# ESP32S31_RADIO register map
Vendor: Espressif; Series: ESP32-S31; File version: 3.52
Registers are 32-bit, read-write, no defined reset value unless marked. A register's access mark holds for its fields unless they carry their own. Offsets are from the block's base; [hi:lo] are bit positions.

## WIFI_MAC_POWER_INTERRUPT — WDEVPWR interrupt bank named by complete print_isr_regs. Complete hal_pwr_interrupt_get_event and hal_pwr_interrupt_clr_event independently prove the masked STATUS read and full-width CLEAR acknowledgement transaction. Complete TSF timer enable/disable leaves update the timer interrupt masks in ENABLE and clear stale events through CLEAR.
Base 0x2010D8B4
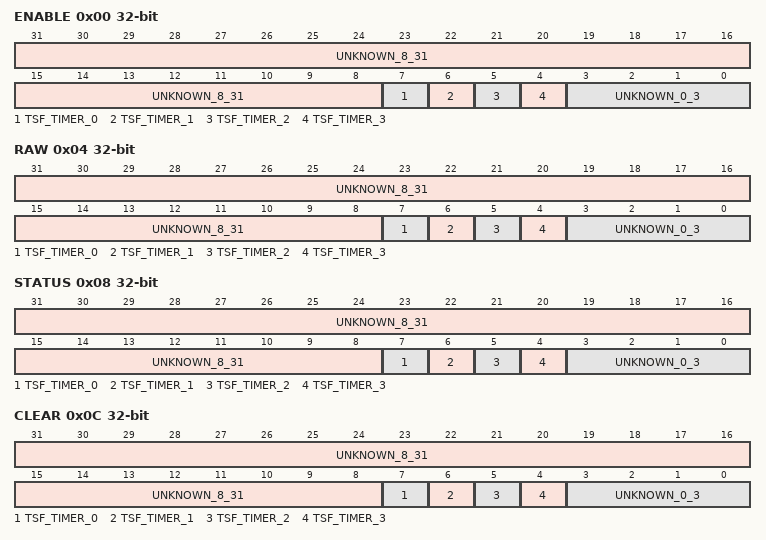
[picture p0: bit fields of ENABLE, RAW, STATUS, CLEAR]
0x00 ENABLE — WDEVPWR_ENABLE diagnostic snapshot and writable event mask. Complete guarded TSF-timer leaves independently identify bits 7 through 4.
  [31:8] UNKNOWN_8_31 — Enable bits whose event identities remain unknown.
  [7] TSF_TIMER_0 — Enable the guarded TSF timer-zero event.
  [6] TSF_TIMER_1 — Enable the guarded TSF timer-one event.
  [5] TSF_TIMER_2 — Enable the guarded TSF timer-two event.
  [4] TSF_TIMER_3 — Enable the guarded TSF timer-three event.
  [3:0] UNKNOWN_0_3 — Enable bits whose event identities remain unknown.
0x04 RAW ro — WDEVPWR_RAW diagnostic snapshot with the same event geometry as ENABLE, STATUS and CLEAR.
  [31:8] UNKNOWN_8_31 — Raw event bits whose identities remain unknown.
  [7] TSF_TIMER_0 — Raw guarded TSF timer-zero event.
  [6] TSF_TIMER_1 — Raw guarded TSF timer-one event.
  [5] TSF_TIMER_2 — Raw guarded TSF timer-two event.
  [4] TSF_TIMER_3 — Raw guarded TSF timer-three event.
  [3:0] UNKNOWN_0_3 — Raw event bits whose identities remain unknown.
0x08 STATUS ro — Masked WDEVPWR event image returned by complete hal_pwr_interrupt_get_event, with TSF timer causes identified by the guarded timer leaves.
  [31:8] UNKNOWN_8_31 — Masked event bits whose identities remain unknown.
  [7] TSF_TIMER_0 — Masked guarded TSF timer-zero event.
  [6] TSF_TIMER_1 — Masked guarded TSF timer-one event.
  [5] TSF_TIMER_2 — Masked guarded TSF timer-two event.
  [4] TSF_TIMER_3 — Masked guarded TSF timer-three event.
  [3:0] UNKNOWN_0_3 — Masked event bits whose identities remain unknown.
0x0C CLEAR write-1-clears — Write-one-to-clear event bank used by complete hal_pwr_interrupt_clr_event. Complete guarded TSF-timer leaves independently identify bits 7 through 4.
  [31:8] UNKNOWN_8_31 — Acknowledge event bits whose identities remain unknown.
  [7] TSF_TIMER_0 — Acknowledge the guarded TSF timer-zero event.
  [6] TSF_TIMER_1 — Acknowledge the guarded TSF timer-one event.
  [5] TSF_TIMER_2 — Acknowledge the guarded TSF timer-two event.
  [4] TSF_TIMER_3 — Acknowledge the guarded TSF timer-three event.
  [3:0] UNKNOWN_0_3 — Acknowledge event bits whose identities remain unknown.

## WIFI_MAC_COLD_HANDSHAKE — Cold MAC initialization request/ready handshake and the adjacent two WDEV timer targets recovered from complete ROM leaves.
Base 0x20104DE0
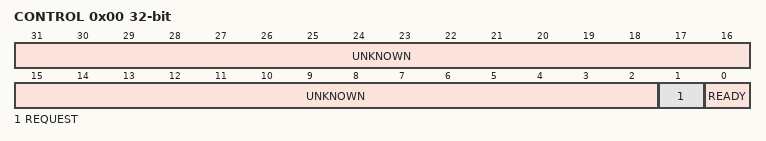
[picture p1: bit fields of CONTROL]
0x00 CONTROL — Software sets REQUEST with a fresh-read RMW, then polls READY before touching the remaining MAC state.
  [31:2] UNKNOWN
  [1] REQUEST — Set before the READY polling loop.
  [0] READY ro — Polled until asserted after REQUEST.
0x10 WDEV_TIMER_TARGET_0_CONTROL — hal_wdev_timer_target_enable selects timer zero with argument zero and replaces enable bit zero.
  [0] ENABLE
0x14 WDEV_TIMER_TARGET_0_VALUE wo — hal_wdev_timer_set_target selects timer zero with argument zero and writes the supplied 32-bit target.
0x18 WDEV_TIMER_TARGET_1_CONTROL — hal_wdev_timer_target_enable selects timer one with argument one and replaces enable bit zero.
  [0] ENABLE
0x1C WDEV_TIMER_TARGET_1_VALUE wo — hal_wdev_timer_set_target selects timer one with argument one and writes the supplied 32-bit target.

## PHY_FECOEX_RECOVERED — Sparse FECOEX words absent from the public platform PAC.
Base 0x20100000
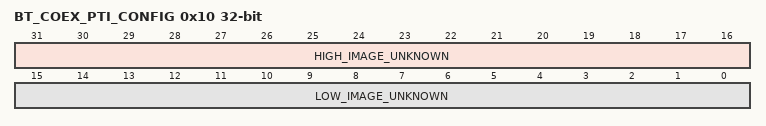
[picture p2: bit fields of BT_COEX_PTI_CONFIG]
0x10 BT_COEX_PTI_CONFIG — Complete coex_pti_v2 performs two ordered fresh-read RMW operations: it first replaces bits 31:16 with 0x0640, then replaces bits 15:0 with 0x0010. Individual bit meanings remain unknown.
  [31:16] HIGH_IMAGE_UNKNOWN — Fixed 0x0640 image published by the first coex_pti_v2 RMW.
    on write: 0x640=REVIEWED_IMAGE (The only high-halfword image proved by coex_pti_v2.)
  [15:0] LOW_IMAGE_UNKNOWN — Fixed 0x0010 image published by the second coex_pti_v2 RMW.
    on write: 16=REVIEWED_IMAGE (The only low-halfword image proved by coex_pti_v2.)
